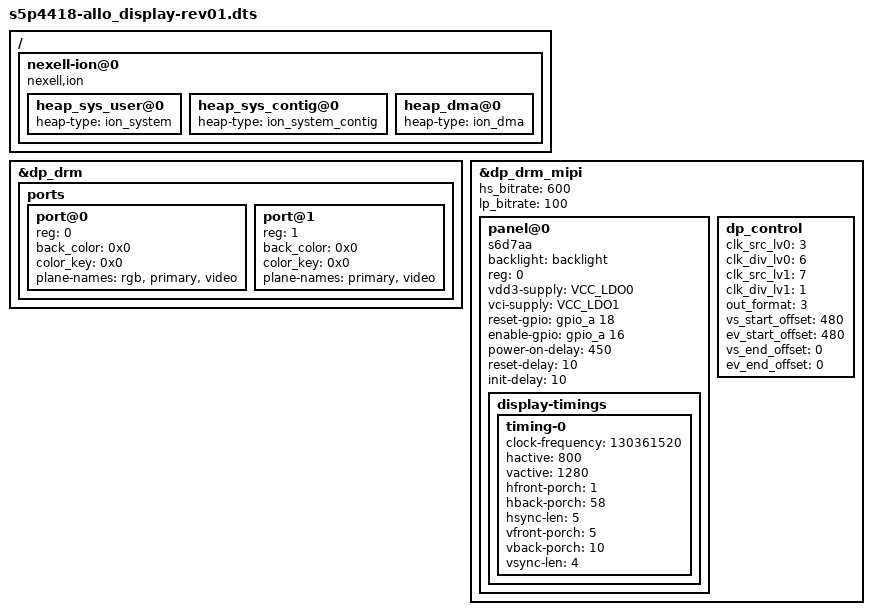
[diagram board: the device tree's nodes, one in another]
/*
 * Copyright (C) 2017  Nexell Co., Ltd.
 * Author: Allan, Park <allan.park@nexell.co.kr>
 *
 * This program is free software; you can redistribute it and/or
 * modify it under the terms of the GNU General Public License
 * as published by the Free Software Foundation; either version 2
 * of the License, or (at your option) any later version.
 *
 * This program is distributed in the hope that it will be useful,
 * but WITHOUT ANY WARRANTY; without even the implied warranty of
 * MERCHANTABILITY or FITNESS FOR A PARTICULAR PURPOSE.  See the
 * GNU General Public License for more details.
 *
 * You should have received a copy of the GNU General Public License
 * along with this program.  If not, see <http://www.gnu.org/licenses/>.
 */

/dts-v1/;
#include "s5p4418-allo_display-common.dtsi"
/ {

	nexell-ion@0 {
		compatible = "nexell,ion";

		heap_sys_user@0 {
			heap-type = "ion_system";
		};

		heap_sys_contig@0 {
			heap-type = "ion_system_contig";
		};

		heap_dma@0 {
			heap-type = "ion_dma";
		};
	};
};

/*
&dp_drm {
    status = "okay";
    ports {
        port@0 {
            reg = <0>;
            back_color = < 0x0 >;
            color_key = < 0x0 >;
            plane-names = "video", "primary", "rgb";
        };
        port@1 {
            reg = <1>;
            back_color = < 0x0 >;
            color_key = < 0x0 >;
            plane-names = "video", "primary";
        };
    };
};
*/
&dp_drm {
    status = "okay";
    ports {
        port@0 {
            reg = <0>;
            back_color = < 0x0 >;
            color_key = < 0x0 >;
            plane-names = "rgb", "primary", "video";
        };
        port@1 {
            reg = <1>;
            back_color = < 0x0 >;
            color_key = < 0x0 >;
            plane-names = "primary", "video";
        };
    };
};

&dp_drm_mipi {
    hs_bitrate = <600>;
    lp_bitrate = <100>;
    status = "ok";

    panel@0 {
        compatible = "s6d7aa";
		backlight = <&backlight>; 
        reg = <0>;
        vdd3-supply = <&VCC_LDO0>;
        vci-supply = <&VCC_LDO1>;
        reset-gpio = <&gpio_a 18 0>;
		enable-gpio = <&gpio_a 16 0>;  /* BL_EN:GPIOA_16 */
/*		enable-gpio2 = <&gpio_d 1 0>;*/
        power-on-delay= <450>;
        reset-delay = <10>;
        init-delay = <10>;
        display-timings {
            timing-0 {
                clock-frequency = <130361520>;
                hactive = <800>;
                vactive = <1280>;
                hfront-porch = <1>;
                hback-porch = <58>;
                hsync-len = <5>;
                vfront-porch = <5>;
                vback-porch = <10>;
                vsync-len = <4>;
            };
        };
    };

    dp_control {
        clk_src_lv0 = <3>;
        clk_div_lv0 = <6>;
        clk_src_lv1 = <7>;
        clk_div_lv1 = <1>;
        out_format = <3>;
        vs_start_offset = <480>;
        ev_start_offset = <480>;
        vs_end_offset = <0>;
        ev_end_offset = <0>;
    };
};


